# psc3m6 register map
Vendor: Infineon Technologies; Series: PSC3M6; File version: 1.0
CPU: CM33 r0p1, little endian, MPU, FPU, DSP, VTOR, 3 interrupt priority bits, 167 interrupts
Registers are 32-bit, read-write, reset 0x0 unless marked. A register's access mark holds for its fields unless they carry their own. Offsets are from the block's base; [hi:lo] are bit positions; {n}, {i} and the like mark numbered series; <NAME> marks a mode.

## SCB0 (part 1 of 2) — Serial Communications Block (SPI/UART/I2C)
Base 0x42820000
Same registers: SCB1 0x42840000, SCB2 0x42850000, SCB3 0x42860000, SCB4 0x42870000, SCB5 0x42C00000
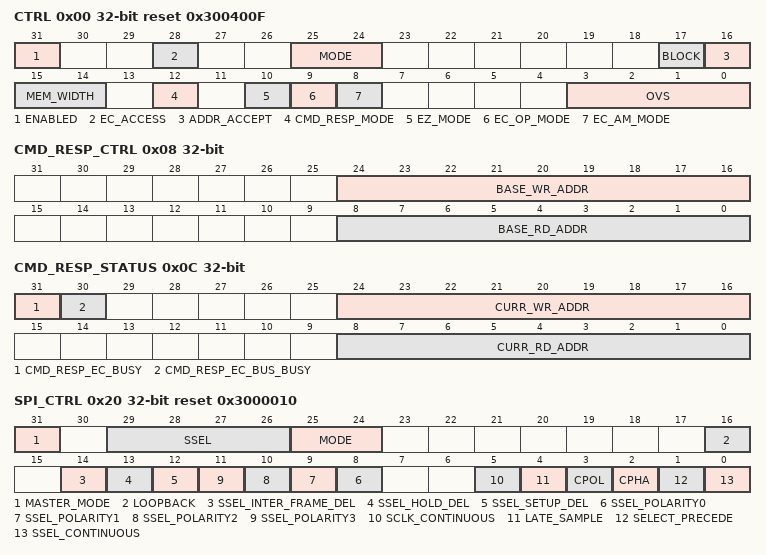
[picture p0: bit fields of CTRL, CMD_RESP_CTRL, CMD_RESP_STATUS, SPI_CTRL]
0x00 CTRL reset 0x300400F — Generic control
  [31] ENABLED — SCB block is enabled ('1') or not ('0'). The proper order in which to initialize SCB is as follows: - Program protocol specific information using SPI_CTRL, UART_CTRL (and UART_TX_CTRL and UART_RX_CTRL) or I2C_CTRL registers. This includes selection of a submode, master/slave functionality and transmitter/receiver functionality when applicable. - Program generic transmitter (TX_CTRL) and receiver (RX_CTRL) information. This includes enabling of the transmitter and receiver functionality. - Program transmitter FIFO (TX_FIFO_CTRL) and receiver FIFO (RX_FIFO_CTRL) information. - Program CTRL register to enable SCB, select the specific operation mode and oversampling factor. Generally when this block is enabled, no control information should be changed. Changes should be made AFTER disabling this block, e.g. to modify the operation mode (from I2C to SPI) or to go from externally to internally clocked. The change takes effect after the block is re-enabled. Note that disabling the block will cause re-initialization of the design and associated state is lost (e.g. FIFO content). Specific to SPI master case, when SCB is idle, below registers can be changed without disabling SCB block, TX_CTRL TX_FIFO_CTRL RX_CTRL RX_FIFO_CTRL SPI_CTRL.SSEL,
  [28] EC_ACCESS — EC_ACCESS is used to enable I2CS_EC or SPIS_EC access to internal EZ memory. 1: enable clk_scb 0: disable clk_scb Just before going to deepsleep this field should be set to 1. when waking up from DeepSleep power mode, and PLL is locked (clk_scb is at expected frequency), this field should be set to 0.
  [25:24] MODE
    0=I2C (Inter-Integrated Circuits (I2C) mode.); 1=SPI (Serial Peripheral Interface (SPI) mode.); 2=UART (Universal Asynchronous Receiver/Transmitter (UART) mode.)
  [17] BLOCK — Only used in externally clocked mode. If the externally clocked logic and the internal CPU accesses to EZ memory coincide/collide, this bit determines whether the CPU access should block and result in bus wait states ('BLOCK is 1') or not (BLOCK is '0'). IF BLOCK is '0' and the accesses collide, CPU read operations return 0xffff:ffff and CPU write operations are ignored. Colliding accesses are registered as interrupt causes: INTR_TX.BLOCKED and INTR_RX.BLOCKED.
  [16] ADDR_ACCEPT — Determines whether a received matching address is accepted in the RX FIFO ('1') or not ('0'). In I2C mode, this field is used to allow the slave to put the received slave address or general call address in the RX FIFO. Note that a received matching address is put in the RX FIFO when this bit is '1' for both I2C read and write transfers. In multi-processor UART receiver mode, this field is used to allow the receiver to put the received address in the RX FIFO. Note: non-matching addresses are never put in the RX FIFO.
  [15:14] MEM_WIDTH
    0=BYTE (8-bit FIFO data elements. This mode provides the biggest amount of FIFO entries, but TX_CTRL.DATA_WIDTH and RX_CTRL.DATA_WIDTH are restricted to [0, 7].); 1=HALFWORD (16-bit FIFO data elements. TX_CTRL.DATA_WIDTH and RX_CTRL.DATA_WIDTH are restricted to [0, 15].); 2=WORD (32-bit FIFO data elements. This mode provides the smallest amount of FIFO entries, but TX_CTRL.DATA_WIDTH and RX_CTRL.DATA_WIDTH can be in a range of [0, 31].); 3=RSVD (N/A)
  [12] CMD_RESP_MODE
  [10] EZ_MODE — Non EZ mode ('0') or EZ mode ('1'). In EZ mode, a meta protocol is applied to the serial interface protocol. This meta protocol adds meaning to the data frames transferred by the serial interface protocol: a data frame can represent a memory address, a write memory data element or a read memory data element. EZ mode is only used for synchronous serial interface protocols: SPI and I2C. In SPI mode, only Motorola submode (all Motorola modes: 0, 1, 2, 3) is supported and the transmitter should use continuous data frames; i.e. data frames not separated by slave deselection. This mode is only applicable to slave functionality. In EZ mode, the slave can read from and write to an addressable memory structure of 32 bytes. In EZ mode, data frames should 8-bit in size and should be transmitted and received with the Most Significant Bit (MSB) first. In UART mode this field should be '0'.
  [9] EC_OP_MODE — This field specifies the clocking for the SCB block '0': Internally clocked mode '1': externally clocked mode In internally clocked mode, the serial interface protocols run off the SCB clock. In externally clocked mode, the serial interface protocols run off the clock as provided by the serial interface. Externally clocked operation mode is only used for synchronous serial interface protocols (SPI and I2C) in slave mode AND EZ mode. In SPI mode, only Motorola submode (all Motorola modes: 0, 1, 2, 3) is supported. The maximum SPI slave, EZ mode bitrate is 48 Mbps (transmission and IO delays outside the IP will degrade the effective bitrate). In UART mode this field should be '0'.
  [8] EC_AM_MODE — This field specifies the clocking for the address matching (I2C) or slave selection detection logic (SPI) '0': Internally clocked mode '1': Externally clocked mode In internally clocked mode, the serial interface protocols run off the SCB clock. In externally clocked mode, the serial interface protocols run off the clock as provided by the serial interface. The clocking for the rest of the logic is determined by CTRL.EC_OP_MODE. Externally clocked mode is only used for synchronous serial interface protocols (SPI and I2C) in slave mode. In SPI mode, only Motorola submode (all Motorola modes: 0, 1, 2, 3) is supported. In UART mode this field should be '0'.
  [3:0] OVS
0x04 STATUS ro reset not defined — Generic status
  [0] EC_BUSY — Indicates whether the externally clocked logic is potentially accessing the EZ memory (this is only possible in EZ mode). This bit can be used by SW to determine whether it is safe to issue a SW access to the EZ memory (without bus wait states (a blocked SW access) or bus errors being generated). Note that the INTR_TX.BLOCKED and INTR_RX.BLOCKED interrupt causes are used to indicate whether a SW access was actually blocked by externally clocked logic.
0x08 CMD_RESP_CTRL — Command/response control
  [24:16] BASE_WR_ADDR — I2C/SPI write base address for CMD_RESP mode. At the start of a write transfer this BASE_WR_ADDR is copied to CMD_RESP_STATUS.CURR_WR_ADDR. This field should not be modified during ongoing bus transfers.
  [8:0] BASE_RD_ADDR — I2C/SPI read base address for CMD_RESP mode. At the start of a read transfer this BASE_RD_ADDR is copied to CMD_RESP_STATUS.CURR_RD_ADDR. This field should not be modified during ongoing bus transfers.
0x0C CMD_RESP_STATUS ro reset not defined — Command/response status
  [31] CMD_RESP_EC_BUSY
  [30] CMD_RESP_EC_BUS_BUSY — Indicates whether there is an ongoing bus transfer to the IP. '0': no ongoing bus transfer. '1': ongoing bus transfer. For SPI, the field is '1' when slave mode is selected. For I2C, the field is set to '1' at a I2C START/RESTART. In case of an address match, the field is set to '0' on a I2C STOP. In case of NO address match, the field is set to '0' after the failing address match.
  [24:16] CURR_WR_ADDR — I2C/SPI write current address for CMD_RESP mode. HW increments the field after a write access to the memory buffer. However, when the last memory buffer address is reached, the address is NOT incremented (but remains at the maximum memory buffer address). The field is used to determine how many bytes have been written (# bytes = CURR_WR_ADDR - CMD_RESP_CTRL.BASE_WR_ADDR). This field is reliable when there is no bus transfer. This field is potentially unreliable when there is a ongoing bus transfer, i.e. when CMD_RESP_EC_BUSY is '0', the field is reliable.
  [8:0] CURR_RD_ADDR — I2C/SPI read current address for CMD_RESP mode. HW increments the field after a read access to the memory buffer. However, when the last memory buffer address is reached, the address is NOT incremented (but remains at the maximum memory buffer address). The field is used to determine how many bytes have been read (# bytes = CURR_RD_ADDR - CMD_RESP_CTRL.BASE_RD_ADDR). This field is reliable when there is no bus transfer. This field is potentially unreliable when there is a ongoing bus transfer, i.e. when CMD_RESP_EC_BUSY is '0', the field is reliable.
0x20 SPI_CTRL reset 0x3000010 — SPI control
  [31] MASTER_MODE
  [29:26] SSEL — Selects one of the four incoming/outgoing SPI slave select signals: - 0: Slave 0, SSEL[0]. - 1: Slave 1, SSEL[1]. - 2: Slave 2, SSEL[2]. - 3: Slave 3, SSEL[3]. - 4: Slave 4, SSEL[4]. - 5: Slave 5, SSEL[5]. - 6: Slave 6, SSEL[6]. - 7: Slave 7, SSEL[7]. - 8: Slave 8, SSEL[8]. - 9 : Slave 9, SSEL[9]. -10:Slave 10, SSEL[10]. -11: Slave 11, SSEL[11]. -12: Slave 12, SSEL[12]. -13: Slave 13, SSEL[13]. -14: Slave 14, SSEL[14]. -15: Slave 15, SSEL[15].
  [25:24] MODE
    0=SPI_MOTOROLA (SPI Motorola submode. In master mode, when not transmitting data (SELECT is inactive), SCLK is stable at CPOL. In slave mode, when not selected, SCLK is ignored; i.e. it can be either stable or clocking. In master mode, when there is no data to transmit (TX FIFO is empty), SELECT is inactive.); 1=SPI_TI (SPI Texas Instruments submode. In master mode, when not transmitting data, SCLK is stable at '0'. In slave mode, when not selected, SCLK is ignored; i.e. it can be either stable or clocking. In master mode, when there is no data to transmit (TX FIFO is empty), SELECT is inactive; i.e. no pulse is generated.); 2=SPI_NS (SPI National Semiconductors submode. In master mode, when not transmitting data, SCLK is stable at '0'. In slave mode, when not selected, SCLK is ignored; i.e. it can be either stable or clocking. In master mode, when there is no data to transmit (TX FIFO is empty), SELECT is inactive.)
  [16] LOOPBACK — Local loopback control (does NOT affect the information on the pins). Only used in master mode. Not used in National Semiconductors submode. '0': No local loopback '1': the SPI master MISO line is connected to the SPI master MOSI line. In other words, in loopback mode the SPI master receives on MISO what it transmits on MOSI.
  [14] SSEL_INTER_FRAME_DEL
  [13] SSEL_HOLD_DEL
  [12] SSEL_SETUP_DEL
  [n+8] SSEL_POLARITY{n} (n=0..3)
  [5] SCLK_CONTINUOUS
  [4] LATE_SAMPLE — Changes the SCLK edge on which MISO is captured in master mode, or MOSI is captured in slave mode. When '0', the default applies, for Motorola as determined by CPOL and CPHA, for Texas Instruments on the falling edge of SCLK(CPOL is '0' and CPHA is '1'), for National Semiconductors on the rising edge of SCLK(CPOL is '0' and CPHA is '0'). When '1', the alternate clock edge is used (which comes half a SPI SCLK period later). for master, applicable to all Motorola, TI and National Semiconductors flavors, and CPOL/CPHA timing mdoes. for slave, applicable to Motorola flavor only, and CPHA=0 timing modes only, and internally-clocked mode only. Late sampling addresses the round trip delay associated with transmitting SCLK from the master to the slave and transmitting MISO from the slave to the master.
  [3] CPOL
  [2] CPHA
  [1] SELECT_PRECEDE — Only used in SPI Texas Instruments' submode. When '1', the data frame start indication is a pulse on the Slave SELECT line that precedes the transfer of the first data frame bit. When '0', the data frame start indication is a pulse on the Slave SELECT line that coincides with the transfer of the first data frame bit.
  [0] SSEL_CONTINUOUS — Continuous SPI data transfers enabled ('1') or not ('0'). This field is used in master mode. In slave mode, both continuous and non-continuous SPI data transfers are supported independent of this field. When continuous transfers are enabled individual data frame transfers are not necessarily separated by slave deselection (as indicated by the level or pulse on the SELECT line): if the TX FIFO has multiple data frames, data frames are send out without slave deselection. When continuous transfers are not enabled individual data frame transfers are always separated by slave deselection: independent of the availability of TX FIFO data frames, data frames are sent out with slave deselection.
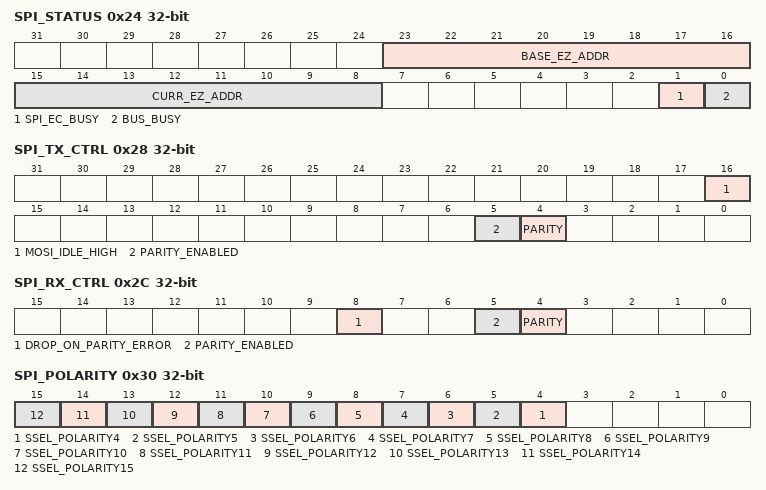
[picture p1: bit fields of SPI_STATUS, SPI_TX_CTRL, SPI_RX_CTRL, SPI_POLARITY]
0x24 SPI_STATUS ro reset not defined
  [23:16] BASE_EZ_ADDR — SPI base EZ address. Address as provided by a SPI write transfer. This field is only reliable in internally clocked mode. In externally clocked mode the field may be unreliable, as clock domain synchronization is not performed in the design.
  [15:8] CURR_EZ_ADDR — SPI current EZ address. Current address pointer. This field is only reliable in internally clocked mode. In externally clocked mode the field may be unreliable (during an ongoing transfer when SPI_EC_BUSY is '1'), as clock domain synchronization is not performed in the design.
  [1] SPI_EC_BUSY — Indicates whether the externally clocked logic is potentially accessing the EZ memory and/or updating BASE_ADDR or CURR_ADDR (this is only possible in EZ mode). This bit can be used by SW to determine whether BASE_ADDR and CURR_ADDR are reliable.
  [0] BUS_BUSY — SPI bus is busy. The bus is considered busy ('1') during an ongoing transaction. For Motorola and National submodes, the busy bit is '1', when the slave selection is activated. For TI submode, the busy bit is '1' from the time the preceding/coinciding slave select is activated for the first transmitted data frame, till the last MOSI/MISO bit of the last data frame is transmitted.
0x28 SPI_TX_CTRL — SPI transmitter control
  [16] MOSI_IDLE_HIGH — SPI master MOSI output level when SELECT output inactive, 0: retain the level of last data bit 1: change to high, (MOSI level is high, before the first data bit time, and after data bit time, defined SSEL/SCLK driving edge with CPOL/CPHA)
  [5] PARITY_ENABLED — Parity generation enabled ('1') or not ('0').
  [4] PARITY — Parity bit. When '0', the transmitter generates an even parity. When '1', the transmitter generates an odd parity.
0x2C SPI_RX_CTRL — SPI receiver control
  [8] DROP_ON_PARITY_ERROR — Behavior when a parity check fails. When '0', received data is send to the RX FIFO. When '1', received data is dropped and lost.
  [5] PARITY_ENABLED — Parity checking enabled ('1') or not ('0').
  [4] PARITY — Parity bit. When '0', the receiver expects an even parity. When '1', the receiver expects an odd parity.
0x30 SPI_POLARITY — SPI polarity control
  [n] SSEL_POLARITY{n} (n=4..15)
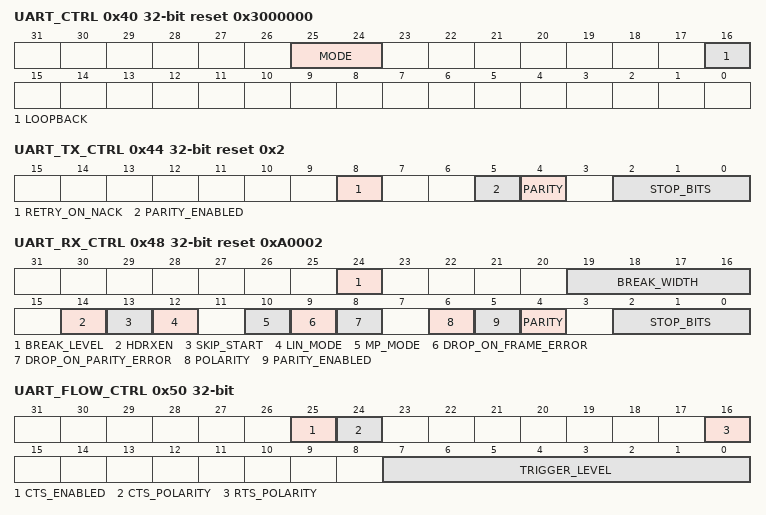
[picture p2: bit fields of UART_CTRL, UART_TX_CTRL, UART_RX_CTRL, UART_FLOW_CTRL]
0x40 UART_CTRL reset 0x3000000 — UART control
  [25:24] MODE
    0=UART_STD (Standard UART submode.); 1=UART_SMARTCARD (SmartCard (ISO7816) submode. Support for negative acknowledgement (NACK) on the receiver side and retransmission on the transmitter side.); 2=UART_IRDA (Infrared Data Association (IrDA) submode. Return to Zero modulation scheme.)
  [16] LOOPBACK — Local loopback control (does NOT affect the information on the pins). 0: Loopback is not enabled 1: UART_TX is connected to UART_RX. UART_RTS is connected to UART_CTS. This allows a SCB UART transmitter to communicate with its receiver counterpart.
0x44 UART_TX_CTRL reset 0x2 — UART transmitter control
  [8] RETRY_ON_NACK — When '1', a data frame is retransmitted when a negative acknowledgement is received. Only applicable to the SmartCard submode.
  [5] PARITY_ENABLED — Parity generation enabled ('1') or not ('0'). Only applicable in standard UART submodes. In SmartCard submode, parity generation is always enabled through hardware. In IrDA submode, parity generation is always disabled through hardware
  [4] PARITY — Parity bit. When '0', the transmitter generates an even parity. When '1', the transmitter generates an odd parity. Only applicable in standard UART and SmartCard submodes.
  [2:0] STOP_BITS — Stop bits. STOP_BITS + 1 is the duration of the stop period in terms of halve bit periods. Valid range is [1, 7]; i.e. a stop period should last at least one bit period.
0x48 UART_RX_CTRL reset 0xA0002 — UART receiver control
  [24] BREAK_LEVEL
  [19:16] BREAK_WIDTH
  [14] HDRXEN
  [13] SKIP_START
  [12] LIN_MODE — Only applicable in standard UART submode. When '1', the receiver performs break detection and baud rate detection on the incoming data. First, break detection counts the amount of bit periods that have a line value of '0'. BREAK_WIDTH specifies the minimum required amount of bit periods. Successful break detection sets the INTR_RX.BREAK_DETECT interrupt cause to '1'. Second, baud rate detection counts the amount of peripheral clock periods that are use to receive the synchronization byte (0x55; least significant bit first). The count is available through UART_RX_STATUS.BR_COUNTER. Successful baud rate detection sets the INTR_RX.BAUD_DETECT interrupt cause to '1' (BR_COUNTER is reliable). This functionality is used to synchronize/refine the receiver clock to the transmitter clock. The receiver software can use the BR_COUNTER value to set the right IP clock (from the programmable clock IP) to guarantee successful receipt of the first LIN data frame (Protected Identifier Field) after the synchronization byte.
  [10] MP_MODE
  [9] DROP_ON_FRAME_ERROR — Behavior when an error is detected in a start or stop period. When '0', received data is sent to the RX FIFO. When '1', received data is dropped and lost.
  [8] DROP_ON_PARITY_ERROR — Behavior when a parity check fails. When '0', received data is sent to the RX FIFO. When '1', received data is dropped and lost. Only applicable in standard UART and SmartCard submodes (negatively acknowledged SmartCard data frames may be dropped with this field).
  [6] POLARITY — Inverts incoming RX line signal. Inversion is after local loopback. This functionality is intended for IrDA receiver functionality.
  [5] PARITY_ENABLED
  [4] PARITY
  [2:0] STOP_BITS — Stop bits. STOP_BITS + 1 is the duration of the stop period in terms of half bit periods. Valid range is [1, 7]; i.e. a stop period should last at least one bit period. Note that in case of a stop bits error, the successive data frames may get lost as the receiver needs to resynchronize its start bit detection. The amount of lost data frames depends on both the amount of stop bits, the idle time between data frames and the data frame value.
0x4C UART_RX_STATUS ro reset not defined — UART receiver status
  [11:0] BR_COUNTER — Amount of SCB clock periods that constitute the transmission of a 0x55 data frame (sent least significant bit first) as determined by the receiver. BR_COUNTER / 8 is the amount of SCB clock periods that constitute a bit period. This field has valid data when INTR_RX.BAUD_DETECT is set to '1'.
0x50 UART_FLOW_CTRL — UART flow control
  [25] CTS_ENABLED — Enable use of CTS input signal by the UART transmitter: '0': Disabled. The UART transmitter ignores the CTS input signal and transmits when a data frame is available for transmission in the TX FIFO or the TX shift register. '1': Enabled. The UART transmitter uses CTS input signal to qualify the transmission of data. It transmits when CTS input signal is active and a data frame is available for transmission in the TX FIFO or the TX shift register. If UART_CTRL.LOOPBACK is '1', the CTS input signal is driven by the RTS output signal locally in SCB (both signals are subjected to signal polarity changes are indicated by RTS_POLARITY and CTS_POLARITY).
  [24] CTS_POLARITY — Polarity of the CTS input signal '0': CTS is active low ; '1': CTS is active high;
  [16] RTS_POLARITY — Polarity of the RTS output signal: '0': RTS is active low; '1': RTS is active high; During SCB reset (Hibernate system power mode), RTS output signal is '1'. This represents an inactive state assuming an active low polarity.
  [7:0] TRIGGER_LEVEL — Trigger level. When the receiver FIFO has less entries than the amount of this field, a Ready To Send (RTS) output signal is activated. By setting this field to '0', flow control is effectively disabled (may be useful for debug purposes).
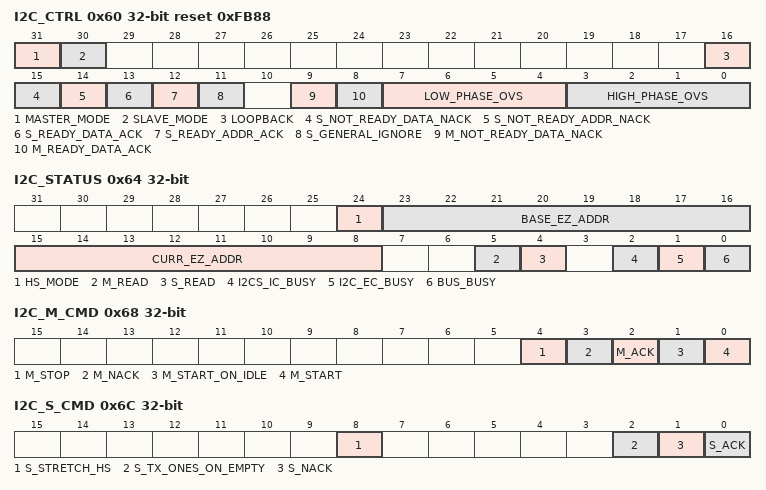
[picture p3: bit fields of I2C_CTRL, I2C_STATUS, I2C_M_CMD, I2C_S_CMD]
0x60 I2C_CTRL reset 0xFB88 — I2C control
  [31] MASTER_MODE
  [30] SLAVE_MODE
  [16] LOOPBACK — Local loopback control (does NOT affect the information on the pins). Only applicable in master/slave mode. When '0', no loopback When '1', loopback is enabled internally in the peripheral, and as a result unaffected by other I2C devices. This allows a SCB I2C peripheral to address itself.
  [15] S_NOT_READY_DATA_NACK — Only used when: - non EZ mode Functionality is as follows: - 1: a received data element byte the slave is immediately NACK'd when the receiver FIFO is full. - 0: clock stretching is performed (till the receiver FIFO is no longer full).
  [14] S_NOT_READY_ADDR_NACK — This field is used during an address match or general call address in internally clocked mode Only used when: - EC_AM_MODE is '0', EC_OP_MODE is '0', S_GENERAL_IGNORE is '0] and non EZ mode. Functionality is as follows: - 1: a received (matching) slave address is immediately NACK'd when the receiver FIFO is full. - 0: clock stretching is performed (till the receiver FIFO is no longer full). For externally clocked logic (EC_AM is '1') on an address match or general call address (and S_GENERAL_IGNORE is '0'). Only used when (NOT used when EC_AM is '1' and EC_OP is '1' and address match and EZ mode): - EC_AM is '1' and EC_OP is '0'. - EC_AM is '1' and general call address match. - EC_AM is '1' and non EZ mode. Functionality is as follows: - 1: a received (matching or general) slave address is always immediately NACK'd. There are two possibilities: 1). the SCB clock is available (in Active system power mode) and it handles the rest of the current transfer. In this case the I2C master will not observe the NACK. 2).SCB clock is not present (in DeepSleep system power mode). In this case the I2C master will observe the NACK and may retry the transfer in the future (which gives the internally clocked logic the time to wake up from DeepSleep system power mode). - 0: clock stretching is performed (till the SCB clock is available). The logic will handle the ongoing transfer as soon as the clock is enabled.
  [13] S_READY_DATA_ACK
  [12] S_READY_ADDR_ACK
  [11] S_GENERAL_IGNORE
  [9] M_NOT_READY_DATA_NACK
  [8] M_READY_DATA_ACK
  [7:4] LOW_PHASE_OVS — Serial I2C interface low phase oversampling factor. LOW_PHASE_OVS + 1 SCB clock periods constitute the low phase of a bit period. The valid range is [7, 15] with input signal median filtering and [6, 15] without input signal median filtering. The field is only used in master mode. In slave mode, the field is NOT used. However, there is a frequency requirement for the SCB clock wrt. the regular (no stretching) interface (IF) low time to guarantee functionally correct behavior. With input signal median filtering, the IF low time should be >= 8 SCB clock cycles and <= 16 IP clock cycles. Without input signal median filtering, the IF low time should be >= 7 SCB clock cycles and <= 16 SCB clock cycles. in slave mode, this field is used to define number of clk_scb cycles for tSU-DAT timing (from ACK/NACK/data ready, to SCL rising edge (released from I2C slave clock stretching))
  [3:0] HIGH_PHASE_OVS — Serial I2C interface high phase oversampling factor. HIGH_PHASE_OVS + 1 SCB clock periods constitute the high phase of a bit period. The valid range is [5, 15] with input signal median filtering and [4, 15] without input signal median filtering. The field is only used in master mode. In slave mode, the field is NOT used. However, there is a frequency requirement for the SCB clock wrt. the regular interface (IF) high time to guarantee functional correct behavior. With input signal median filtering, the IF high time should be >= 6 SCB clock cycles and <= 16 SCB clock cycles. Without input signal median filtering, the IF high time should be >= 5 SCB clock cycles and <= 16 SCB clock cycles.
0x64 I2C_STATUS ro (reset mask 0x1000035)
  [24] HS_MODE
  [23:16] BASE_EZ_ADDR
  [15:8] CURR_EZ_ADDR
  [5] M_READ
  [4] S_READ
  [2] I2CS_IC_BUSY
  [1] I2C_EC_BUSY
  [0] BUS_BUSY — I2C bus is busy. The bus is considered busy ('1'), from the time a START is detected or from the time the SCL line is '0'. The bus is considered idle ('0'), from the time a STOP is detected. If SCB block is disabled, BUS_BUSY is '0'. After enabling the block, it takes time for the BUS_BUSY to detect a busy bus. This time is the maximum high time of the SCL line. For a 100 kHz interface frequency, this maximum high time may last roughly 5 us (half a bit period). For single master systems, BUS_BUSY does not have to be used to detect an idle bus before a master starts a transfer using I2C_M_CMD.M_START (no bus collisions). For multi-master systems, BUS_BUSY can be used to detect an idle bus before a master starts a transfer using I2C_M_CMD.M_START_ON_IDLE (to prevent bus collisions).
0x68 I2C_M_CMD — I2C master command
  [4] M_STOP — When '1', attempt to transmit a STOP. When this action is performed, the hardware sets this field to '0'. I2C_M_CMD.M_START has a higher priority than this command: in situations where both a STOP and a REPEATED START could be transmitted, M_START takes precedence over M_STOP.
  [3] M_NACK — for I2C master, the NACKed byte should be properly received. it write the data byte, before ACK/NACK decision. When '1', attempt to transmit a negative acknowledgement (NACK). if the reciever FIFO is full (the received data byte cannot be written), it stretch SCL(extend SCL low phase) until the receiver FIFO changes to not full, to write the last byte, then send out NACK. When this action is performed, the hardware sets this field to '0'.
  [2] M_ACK — When '1', attempt to transmit an acknowledgement (ACK). When this action is performed, the hardware sets this field to '0'.
  [1] M_START_ON_IDLE — When '1', transmit a START as soon as the bus is idle (I2C_STATUS.BUS_BUSY is '0', note that BUSY has a default value of '0'). For bus idle detection the hardware relies on STOP detection. As a result, bus idle detection is only functional after at least one I2C bus transfer has been detected on the bus (default/reset value of BUSY is '0') . A START is only transmitted when the master state machine is in the default state. When this action is performed, the hardware sets this field to '0'.
  [0] M_START — When '1', transmit a START or REPEATED START. Whether a START or REPEATED START is transmitted depends on the state of the master state machine. A START is only transmitted when the master state machine is in the default state. A REPEATED START is transmitted when the master state machine is not in the default state, but is working on an ongoing transaction. The REPEATED START can only be transmitted after a NACK or ACK has been received for a transmitted data element or after a NACK has been transmitted for a received data element. When this action is performed, the hardware sets this field to '0'.
0x6C I2C_S_CMD — I2C slave command
  [8] S_STRETCH_HS — When '1', attempt to stretch SCL at time t1, SCL falling edge after 'START, Master-code, NACK' pattern is detected. When I2C_CTRL.HS_ENABLED is set, it should be set; after wakeup from DeepSleep power mode, it should also be set. When INTR_S.I2C_HS_ENTER triggers, firmware configure clk_scb to meet I2C Hs-mode timing requirements, then firmware can clear this bit.
  [2] S_TX_ONES_ON_EMPTY — When '1', attempt to send ones when TX_FIFO is empty. Once hardware starts to send ones, it will continue send ones until NACK is received, regardless of TX_FIFO status (even if new data is written into TX_FIFO). This bit is used to avoid stretching SCL, which is not expected for some master devices.
  [1] S_NACK — When '1', attempt to transmit a negative acknowledgement (NACK). When this action is performed, the hardware sets this field to '0'. In EZ mode, this field should be set to '0' (it is only to be used in non EZ mode). This command has a higher priority than I2C_S_CMD.S_ACK, I2C_CTRL.S_READY_ADDR_ACK or I2C_CTRL.S_READY_DATA_ACK.
  [0] S_ACK — When '1', attempt to transmit an acknowledgement (ACK). When this action is performed, the hardware sets this field to '0'. In EZ mode, this field should be set to '0' (it is only to be used in non EZ mode).
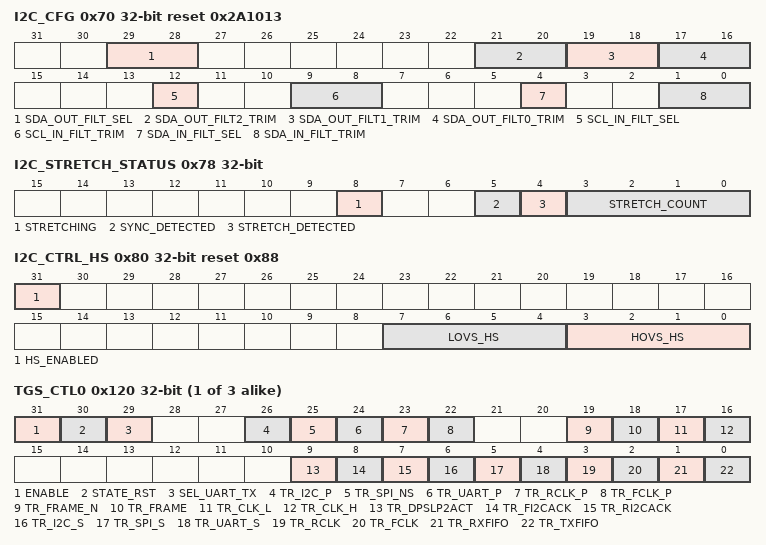
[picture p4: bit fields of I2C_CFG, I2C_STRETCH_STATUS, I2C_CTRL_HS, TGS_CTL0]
0x70 I2C_CFG reset 0x2A1013 — I2C configuration
  [29:28] SDA_OUT_FILT_SEL — Selection of cumulative filter delay on SDA output to meet tHD_DAT parameter '0': 0 ns. '1': 50 ns (filter 0 enabled). '2': 100 ns (filters 0 and 1 enabled). '3': 150 ns (filters 0, 1 and 2 enabled).
  [21:20] SDA_OUT_FILT2_TRIM — Trim settings for the 50ns delay filter on SDA output used to guarantee tHD_DAT I2C parameter. Default setting meets the I2C spec. Programmability available if required
  [19:18] SDA_OUT_FILT1_TRIM — Trim settings for the 50ns delay filter on SDA output used to guarantee tHD_DAT I2C parameter. Default setting meets the I2C spec. Programmability available if required
  [17:16] SDA_OUT_FILT0_TRIM — Trim settings for the 50ns delay filter on SDA output used to guarantee tHD_DAT I2C parameter. Default setting meets the I2C spec. Programmability available if required
  [12] SCL_IN_FILT_SEL — Enable for 50ns glitch filter on SCL input '0': 0 ns. '1: 50 ns (filter enabled).
  [9:8] SCL_IN_FILT_TRIM — Trim settings for the 50ns glitch filter on the SDA input. Default setting meets the I2C glitch rejections specs. Programmability available if required
  [4] SDA_IN_FILT_SEL — Enable for 50ns glitch filter on SDA input '0': 0 ns. '1: 50 ns (filter enabled).
  [1:0] SDA_IN_FILT_TRIM — Trim settings for the 50ns glitch filter on the SDA input. Default setting meets the I2C glitch rejections specs. Programmability available if required
0x74 I2C_STRETCH_CTRL — I2C stretch control
  [3:0] STRETCH_THRESHOLD
0x78 I2C_STRETCH_STATUS ro
  [8] STRETCHING, [5] SYNC_DETECTED, [4] STRETCH_DETECTED, [3:0] STRETCH_COUNT
0x80 I2C_CTRL_HS reset 0x88 — I2C control for High-Speed mode
  [31] HS_ENABLED, [7:4] LOVS_HS, [3:0] HOVS_HS
{0x120+0xC*i} TGS_CTL{i} (i=0..2) — Timeout generation support {i} control
  [31] ENABLE — TGS feature enable '0': not used '1': TGS feature is enabled and the counter reacts on trigger conditions When CTRL.EC_ACCESS is 1'b1, TGS interrupts are blocked and not triggered, even in active power state.
  [30] STATE_RST — timer underflow generates a SCB communication and FIFO reset additionally to the IRQ '0': not used '1': state and FIFO reset enabled This bit is only applicable to the I2C slave only configuration. However, TGS feature is applicable for all the protocols.
  [29] SEL_UART_TX — Select one UART direction for the counter (either Tx or Rx UART) '0': RX triggers are used for the counter '1': TX triggers are used for the counter
  [26] TR_I2C_P — trigger pulse stops the counter when I2C stop condition is detected '0': not used '1': counter stopped when I2C stop condition detected
  [25] TR_SPI_NS — trigger pulse stops the counter with rising edge of NSS '0': not used '1': counter stopped when rising edge of NSS detected TGS is not supported in SPI Master mode with multi-slave selection
  [24] TR_UART_P — trigger pulse stops the counter due to detected UART stop bit (TX/RX UART is controlled by SEL_UART_TX reg) UART RX frame errors are considered as stop condition in RX mode '0': not used '1': counter stopped when UART stop bit detected or frame error in RX mode occured
  [23] TR_RCLK_P — trigger pulse stops the counter in case of rising edge on SCL/SCLK '0': not used '1': counter stopped when rising edge of SCL/SCLK
  [22] TR_FCLK_P — trigger pulse stops the counter in case of falling edge on SCL/SCLK '0': not used '1': counter stopped when falling edge of SCL/SCLK
  [19] TR_FRAME_N — counter is gated outside active frame (In case of UART frame, TX/RX selection is controlled by SEL_UART_TX reg) '0': not used '1': gated outside active frame
  [18] TR_FRAME — counter is gated during active frame (In case of UART frame, TX/RX selection is controlled by SEL_UART_TX reg) '0': not used '1': gated during active frame
  [17] TR_CLK_L — counter is gated while clock signal is at LOW level '0': not used '1': gated while clock signal is at LOW level
  [16] TR_CLK_H — counter is gated while clock signal is at HIGH level '0': not used '1': gated while clock signal is at HIGH level
  [9] TR_DPSLP2ACT — trigger pulse reloads the counter in case of power state transition from DeepSleep to Active '0': not used '1': DeepSleep to Active power state transition (by rst_act_n assertion)
  [8] TR_FI2CACK — trigger pulse reloads the counter in case of transmitted/received I2C ACK on the falling edge on SCL '0': not used '1': ACK on the falling edge of I2C SCL Should not be combined with the stop trigger TR_FCLK_P as both of them happen at the falling edge of SCL
  [7] TR_RI2CACK — trigger pulse reloads the counter in case of transmitted/received I2C ACK on the rising edge of SCL '0': not used '1': ACK on the rising edge of I2C SCL Should not be combined with the stop trigger TR_RCLK_P as both of them happen at the rising edge of SCL
  [6] TR_I2C_S — trigger pulse reloads the counter in case of I2C start / repeated start condition '0': not used '1': I2C start / repeated start condition detected
  [5] TR_SPI_S — trigger pulse reloads the counter in case of falling edge on SPI NSS '0': not used '1': falling edge on SPI NSS TGS is not supported in SPI Master mode with multi-slave selection
  [4] TR_UART_S — trigger pulse reloads the counter in case of falling edge on UART start bit (TX/RX UART is controlled by SEL_UART_TX reg) '0': not used '1': falling edge of UART start bit
  [3] TR_RCLK — trigger pulse reloads the counter in case of rising edge on SCL/SCLK '0': not used '1': rising edge of SCL/SCLK
  [2] TR_FCLK — trigger pulse reloads the counter in case of falling edge on SCL/SCLK '0': not used '1': falling edge of SCL/SCLK
  [1] TR_RXFIFO — trigger pulse reloads the counter in case another byte is received (from external) '0': not used '1': falling edge of RX Buffer write request in CMD_RESP and EZ modes or rising edge of RX Buffer write acknowledment in FIFO mode
  [0] TR_TXFIFO — trigger pulse reloads the counter in case another byte is transmitted (to external) '0': not used '1': falling edge of TX Buffer read request in CMD_RESP and EZ modes or rising edge of TX Buffer read acknowledgment in FIFO mode
